AUTOSAR XML (schema 4-2-2)
package /AUTOLIV/SoftwareComponents/RCM
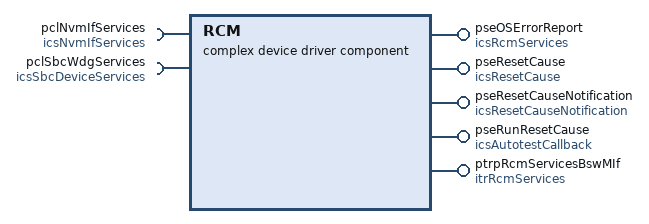
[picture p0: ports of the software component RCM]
  complex device driver sw component type RCM: category=BSW_Complex_Device_Drivers  # RCM_AC_ResetCauseManagement
    require port pclNvmIfServices: required-interface=icsNvmIfServices  # # Architecture Element ID - ARCH_SW_RCM_pclNvmIfServices_SetRamBlockStatus # Description - The NvmIfServices_SetRamBlockStatus interface will set a flag, flag used to notify that the ECC Counters Block has to be recorded in the EEPROM during the shutdown. (The writhing procces will be done in NvM_WriteAll();) # Data Flow ## Inputs - {Reset Counter} ## Outputs - {Value of flag} # Linked Runnable - RCM_Autotest_ResetCause #Traceability
      required-com-specs:
        GetNvmBlockLength
        GetNvmBlockStatus
        ReadBlockByAddress
        RestorePRAMBlockDefaults
        SetRamBlockStatus
        WriteBlockByAddress
        WriteNvmBlock
    require port pclSbcWdgServices: client-com-spec=GetSbcStatus, required-interface=icsSbcDeviceServices  # # Architecture Element ID - ARCH_SW_RCM_pclSbcWdgServices_GetSbcStatus_RCM_DetermineResetCause # Description - The SBC_GetSBCStatusInformation interface will read a SBC flag to determine the reset cause # Data Flow ## Inputs - {SBC flag} ## Outputs # Linked Runnable - RCM_DetermineResetCause #Traceability FUSA_SM_S32K1XXSM_301, FUSA_SM_S32K1XXSM_305
    5 x provide port:
      pseOSErrorReport: server-com-spec{operation=ReportOsErrorStatus, queue-length=1}, provided-interface=icsRcmServices  # # Architecture Element ID ARCH_SW_Rcm_pseOSErrorReport_RCM_ReportOSError # Description - The RCM_ReportOSError runnable shall be called in the ErrorHook runnable in order to send the Os error code and task id # Data Flow ## Inputs ## Outputs - {Task ID} - {Os error code} # Linked Runnable - RCM_ReportOSError #Traceability FUSA_SM_S32K1XXSM_301, FUSA_SM_S32K1XXSM_305
      pseResetCause: provided-com-specs=[{operation=DetermineResetCause, queue-length=1}, {operation=GetResetCause, queue-length=1}], provided-interface=icsResetCause  # # Architecture Element ID - ARCH_SW_MIC_pseResetCause_GetResetCause # Description - The GetResetCause interface will get the active reset cause. The function will return the SBC wakeup flags, application reset flags and the Mcu reset flags. # Data Flow ## Inputs ## Outputs - {Reset Cause} can be: - KU32_RESET_CAUSE_UNKNOWN - KU32_SBC_POR_MASK - KU32_SBC_GPIO_WK_WU_MASK - KU32_SBC_WK_WU_MASK - KU32_SBC_TIMER_WU_MASK - KU32_SBC_CAN_WU_MASK - KU32_MCU_LOW_VOLTAGE_DETECT_RESET_MASK - KU32_MCU_LOSS_OF_CLOCK_RESET_MASK - KU32_MCU_LOSS_OF_LOCK_RESET_MASK - KU32_MCU_WATCHDOG_RESET_MASK - KU32_MCU_EXTERNAL_RESET_PIN_MASK - KU32_MCU_POWER_ON_RESET_MASK - KU32_MCU_JTAG_GENERATED_RESET_MASK - KU32_MCU_CORE_LOCKUP_RESET_MASK - KU32_MCU_SOFTWARE_RESET_MASK - KU32_MCU_MDM_AP_SYSTEM_RESET_REQUESTED_MASK - KU32_MCU_STOP_ACKNOWLEDGE_ERROR_RESET_MASK - KU32_APP_INVALID_INTERRUPT_NOTIFICACTION_MASK - KU32_APP_OS_EXCEPTION_NOTIFICATION_MASK - KU32_APP_BATTERY_LOSS_NOTIFICATION_MASK - KU32_APP_ECC_RAM_NOTIFICATION_MASK - KU32_APP_ECC_PFLASH_NOTIFICATION_MASK - KU32_APP_ECC_E2P_NOTIFICATION_MASK - KU32_APP_ECC_UNIDENTIFIED_NOTIFICATION_MASK - KU32_APP_MACHINE_EXCEPTION_NOTIFICATION_MASK - KU32_APP_SW_WDG_TEST_NOTIFICATION_MASK - KU32_APP_WAKE_UP_EVENT_NOTIFICATION_MASK - KU32_APP_BLTD_RESET_NOTIFICATION_MASK - KU32_APP_STACK_OVERFLOW_NOTIFICATION_MASK - KU32_APP_RAM_DATA_CORRUPTED_NOTIFICATION_MASK - KU32_APP_DIAG_HARD_RESET_NOTIFICATION_MASK - KU32_APP_DIAG_SOFT_RESET_NOTIFICATION_MASK # Linked Runnable RCM_GetResetCause #Traceability FUSA_SM_S32K1XXSM_301, FUSA_SM_S32K1XXSM_305
      pseResetCauseNotification: server-com-spec{operation=NotifyResetCause, queue-length=1}, provided-interface=icsResetCauseNotification  # # Architecture Element ID - ARCH_SW_MIC_pseResetCauseNotification_NotifyResetCause # Description - The ResetCauseNotification_NotifyResetCause interface will notify active reset cause. # Data Flow ## Inputs - {Reset Cause} can be : - KU32_INVALID_INTERRUPT_NOTIFICATION - KU32_OS_EXCEPTION_NOTIFICATION - KU32_BATTERY_LOSS_NOTIFICATION - KU32_ECC_RAM_NOTIFICATION - KU32_ECC_PFLASH_NOTIFICATION - KU32_ECC_E2P_NOTIFICATION - KU32_ECC_UNIDENTIFIED_NOTIFICATION - KU32_MACHINE_EXCEPTION_NOTIFICATION - KU32_SW_WDG_TEST_NOTIFICATION - KU32_WAKE_UP_EVENT_NOTIFICATION - KU32_BTLD_RESET_NOTIFICATION - KU32_STACK_OVERFLOW_NOTIFICATION - KU32_RAM_DATA_CORRUPTED_NOTIFICATION - KU32_DIAG_HARD_RESET_NOTIFICATION - KU32_DIAG_SOFT_RESET_NOTIFICATION ## Outputs # Linked Runnable - RCM_NotifyResetCause #Traceability FUSA_SM_S32K1XXSM_301, FUSA_SM_S32K1XXSM_305
      pseRunResetCause: server-com-spec{operation=AutotestCallback, queue-length=1}, provided-interface=icsAutotestCallback  # # Architecture Element ID ARCH_SW_RCM_pseRunExtWDTest_RCM_Autotest_ResetCause # Description - The RCM_Autotest_ResetCauserunnable shall be called in the ATM services runnable upon autotest execution # Data Flow # Linked Runnable - RCM_Autotest_ResetCause #Traceability FUSA_SM_S32K1XXSM_301, FUSA_SM_S32K1XXSM_305
      ptrpRcmServicesBswMIf: provided-interface=itrRcmServices  # # Architecture Element ID ARCH_SW_Rcm_ptrpRcmServicesBswMIf_RCM_DetermineResetCause # Description - The RCM_DetermineResetCause runnable shall be called in the BswM_OnStartComEffective runnable in order to determine the current reset cause # Data Flow # Linked Runnable - RCM_DetermineResetCause #Traceability DOM_eCS_TF_H_215, DOM_eCS_TF_H_216, DOM_eCS_TF_H_217, FUSA_SM_S32K1XXSM_301, FUSA_SM_S32K1XXSM_305 -------------------------------------------------------------------------------------------------------------------------------------------------
